AUTOSAR XML (schema 4-2-2)
package /STELLANTIS/EPT/ASWCs
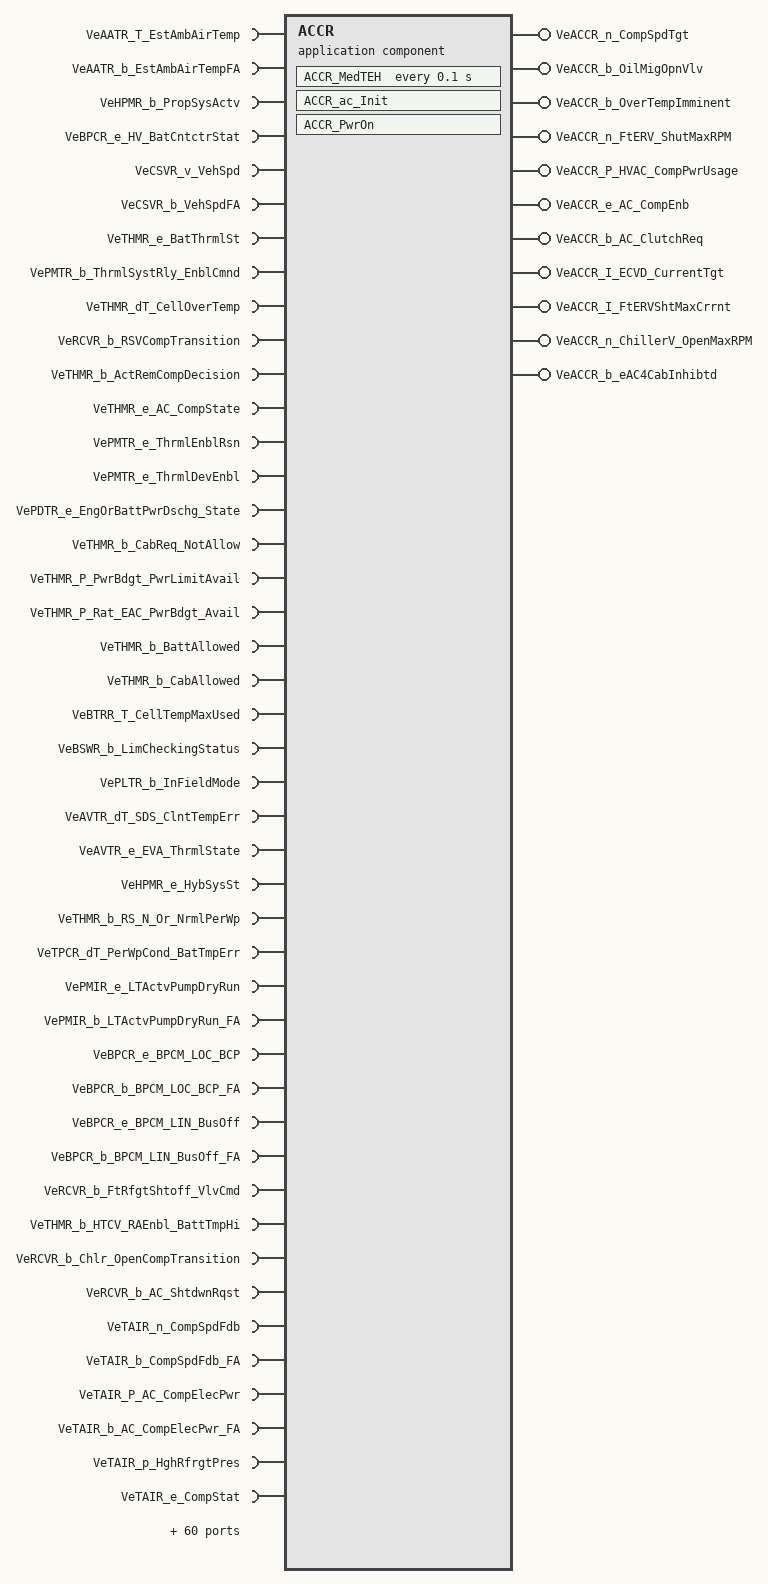
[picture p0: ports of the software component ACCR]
  application sw component type ACCR
    104 x require port:
      VeAATR_T_EstAmbAirTemp: variation-point={short-label=vpVeAATR_T_EstAmbAirTemp, sw-syscond=1}, nonqueued-receiver-com-spec{data-element=Value, init-value=0}, required-interface=VeAATR_T_EstAmbAirTemp
      VeAATR_b_EstAmbAirTempFA: variation-point={short-label=vpVeAATR_b_EstAmbAirTempFA, sw-syscond=1}, nonqueued-receiver-com-spec{data-element=Value, init-value=0}, required-interface=VeAATR_b_EstAmbAirTempFA
      VeHPMR_b_PropSysActv: variation-point={short-label=vpVeHPMR_b_PropSysActv, sw-syscond=1}, nonqueued-receiver-com-spec{data-element=Value, init-value=0}, required-interface=VeHPMR_b_PropSysActv
      VeBPCR_e_HV_BatCntctrStat: variation-point={short-label=vpVeBPCR_e_HV_BatCntctrStat, sw-syscond=1}, nonqueued-receiver-com-spec{data-element=Value, init-value=CeHVTR_e_Open}, required-interface=VeBPCR_e_HV_BatCntctrStat
      VeCSVR_v_VehSpd: variation-point={short-label=vpVeCSVR_v_VehSpd, sw-syscond=1}, nonqueued-receiver-com-spec{data-element=Value, init-value=0}, required-interface=VeCSVR_v_VehSpd
      VeCSVR_b_VehSpdFA: variation-point={short-label=vpVeCSVR_b_VehSpdFA, sw-syscond=1}, nonqueued-receiver-com-spec{data-element=Value, init-value=0}, required-interface=VeCSVR_b_VehSpdFA
      VeTHMR_e_BatThrmlSt: variation-point={short-label=vpVeTHMR_e_BatThrmlSt, sw-syscond=1}, nonqueued-receiver-com-spec{data-element=Value, init-value=CeTHMR_e_NoConditioning}, required-interface=VeTHMR_e_BatThrmlSt
      VePMTR_b_ThrmlSystRly_EnblCmnd: variation-point={short-label=vpVePMTR_b_ThrmlSystRly_EnblCmnd, sw-syscond=1}, nonqueued-receiver-com-spec{data-element=Value, init-value=0}, required-interface=VePMTR_b_ThrmlSystRly_EnblCmnd
      VeTHMR_dT_CellOverTemp: variation-point={short-label=vpVeTHMR_dT_CellOverTemp, sw-syscond=1}, nonqueued-receiver-com-spec{data-element=Value, init-value=0}, required-interface=VeTHMR_dT_CellOverTemp
      VeRCVR_b_RSVCompTransition: variation-point={short-label=vpVeRCVR_b_RSVCompTransition, sw-syscond=1}, nonqueued-receiver-com-spec{data-element=Value, init-value=0}, required-interface=VeRCVR_b_RSVCompTransition
      VeTHMR_b_ActRemCompDecision: variation-point={short-label=vpVeTHMR_b_ActRemCompDecision, sw-syscond=1}, nonqueued-receiver-com-spec{data-element=Value, init-value=0}, required-interface=VeTHMR_b_ActRemCompDecision
      VeTHMR_e_AC_CompState: variation-point={short-label=vpVeTHMR_e_AC_CompState, sw-syscond=1}, nonqueued-receiver-com-spec{data-element=Value, init-value=CeTHMR_e_ACOff}, required-interface=VeTHMR_e_AC_CompState
      VePMTR_e_ThrmlEnblRsn: variation-point={short-label=vpVePMTR_e_ThrmlEnblRsn, sw-syscond=1}, nonqueued-receiver-com-spec{data-element=Value, init-value=CePMTR_e_EnblKey_Acc_or_DrvDoorAjr}, required-interface=VePMTR_e_ThrmlEnblRsn
      VePMTR_e_ThrmlDevEnbl: variation-point={short-label=vpVePMTR_e_ThrmlDevEnbl, sw-syscond=1}, nonqueued-receiver-com-spec{data-element=Value, init-value=CePMTR_e_DISBL_All_Thrml}, required-interface=VePMTR_e_ThrmlDevEnbl
      VePDTR_e_EngOrBattPwrDschg_State: variation-point={short-label=vpVePDTR_e_EngOrBattPwrDschg_State, sw-syscond=1}, nonqueued-receiver-com-spec{data-element=Value, init-value=CePDTR_e_No_Dischrg}, required-interface=VePDTR_e_EngOrBattPwrDschg_State
      VeTHMR_b_CabReq_NotAllow: variation-point={short-label=vpVeTHMR_b_CabReq_NotAllow, sw-syscond=1}, nonqueued-receiver-com-spec{data-element=Value, init-value=0}, required-interface=VeTHMR_b_CabReq_NotAllow
      VeTHMR_P_PwrBdgt_PwrLimitAvail: variation-point={short-label=vpVeTHMR_P_PwrBdgt_PwrLimitAvail, sw-syscond=1}, nonqueued-receiver-com-spec{data-element=Value, init-value=0}, required-interface=VeTHMR_P_PwrBdgt_PwrLimitAvail
      VeTHMR_P_Rat_EAC_PwrBdgt_Avail: variation-point={short-label=vpVeTHMR_P_Rat_EAC_PwrBdgt_Avail, sw-syscond=1}, nonqueued-receiver-com-spec{data-element=Value, init-value=0}, required-interface=VeTHMR_P_Rat_EAC_PwrBdgt_Avail
      VeTHMR_b_BattAllowed: variation-point={short-label=vpVeTHMR_b_BattAllowed, sw-syscond=1}, nonqueued-receiver-com-spec{data-element=Value, init-value=0}, required-interface=VeTHMR_b_BattAllowed
      VeTHMR_b_CabAllowed: variation-point={short-label=vpVeTHMR_b_CabAllowed, sw-syscond=1}, nonqueued-receiver-com-spec{data-element=Value, init-value=0}, required-interface=VeTHMR_b_CabAllowed
      VeBTRR_T_CellTempMaxUsed: variation-point={short-label=vpVeBTRR_T_CellTempMaxUsed, sw-syscond=1}, nonqueued-receiver-com-spec{data-element=Value, init-value=0}, required-interface=VeBTRR_T_CellTempMaxUsed
      VeBSWR_b_LimCheckingStatus: variation-point={short-label=vpVeBSWR_b_LimCheckingStatus, sw-syscond=1}, nonqueued-receiver-com-spec{data-element=Value, init-value=0}, required-interface=VeBSWR_b_LimCheckingStatus
      VePLTR_b_InFieldMode: variation-point={short-label=vpVePLTR_b_InFieldMode, sw-syscond=1}, nonqueued-receiver-com-spec{data-element=Value, init-value=0}, required-interface=VePLTR_b_InFieldMode
      VeAVTR_dT_SDS_ClntTempErr: variation-point={short-label=vpVeAVTR_dT_SDS_ClntTempErr, sw-syscond=1}, nonqueued-receiver-com-spec{data-element=Value, init-value=0}, required-interface=VeAVTR_dT_SDS_ClntTempErr
      VeAVTR_e_EVA_ThrmlState: variation-point={short-label=vpVeAVTR_e_EVA_ThrmlState, sw-syscond=1}, nonqueued-receiver-com-spec{data-element=Value, init-value=CeAVTR_e_NoEVACond}, required-interface=VeAVTR_e_EVA_ThrmlState
      VeHPMR_e_HybSysSt: variation-point={short-label=vpVeHPMR_e_HybSysSt, sw-syscond=1}, nonqueued-receiver-com-spec{data-element=Value, init-value=CeHPMR_e_POWERUP}, required-interface=VeHPMR_e_HybSysSt
      VeTHMR_b_RS_N_Or_NrmlPerWp: variation-point={short-label=vpVeTHMR_b_RS_N_Or_NrmlPerWp, sw-syscond=1}, nonqueued-receiver-com-spec{data-element=Value, init-value=0}, required-interface=VeTHMR_b_RS_N_Or_NrmlPerWp
      VeTPCR_dT_PerWpCond_BatTmpErr: variation-point={short-label=vpVeTPCR_dT_PerWpCond_BatTmpErr, sw-syscond=1}, nonqueued-receiver-com-spec{data-element=Value, init-value=0}, required-interface=VeTPCR_dT_PerWpCond_BatTmpErr
      VePMIR_e_LTActvPumpDryRun: variation-point={short-label=vpVePMIR_e_LTActvPumpDryRun, sw-syscond=1}, nonqueued-receiver-com-spec{data-element=Value, init-value=CePMPR_e_FTSNA_False}, required-interface=VePMIR_e_LTActvPumpDryRun
      VePMIR_b_LTActvPumpDryRun_FA: variation-point={short-label=vpVePMIR_b_LTActvPumpDryRun_FA, sw-syscond=1}, nonqueued-receiver-com-spec{data-element=Value, init-value=0}, required-interface=VePMIR_b_LTActvPumpDryRun_FA
      VeBPCR_e_BPCM_LOC_BCP: variation-point={short-label=vpVeBPCR_e_BPCM_LOC_BCP, sw-syscond=1}, nonqueued-receiver-com-spec{data-element=Value, init-value=CeBPCR_e_LOC_BCP_False}, required-interface=VeBPCR_e_BPCM_LOC_BCP
      VeBPCR_b_BPCM_LOC_BCP_FA: variation-point={short-label=vpVeBPCR_b_BPCM_LOC_BCP_FA, sw-syscond=1}, nonqueued-receiver-com-spec{data-element=Value, init-value=0}, required-interface=VeBPCR_b_BPCM_LOC_BCP_FA
      VeBPCR_e_BPCM_LIN_BusOff: variation-point={short-label=vpVeBPCR_e_BPCM_LIN_BusOff, sw-syscond=1}, nonqueued-receiver-com-spec{data-element=Value, init-value=CeBPCR_e_LIN_BusOff_Disabled}, required-interface=VeBPCR_e_BPCM_LIN_BusOff
      VeBPCR_b_BPCM_LIN_BusOff_FA: variation-point={short-label=vpVeBPCR_b_BPCM_LIN_BusOff_FA, sw-syscond=1}, nonqueued-receiver-com-spec{data-element=Value, init-value=0}, required-interface=VeBPCR_b_BPCM_LIN_BusOff_FA
      VeRCVR_b_FtRfgtShtoff_VlvCmd: variation-point={short-label=vpVeRCVR_b_FtRfgtShtoff_VlvCmd, sw-syscond=1}, nonqueued-receiver-com-spec{data-element=Value, init-value=0}, required-interface=VeRCVR_b_FtRfgtShtoff_VlvCmd
      VeTHMR_b_HTCV_RAEnbl_BattTmpHi: variation-point={short-label=vpVeTHMR_b_HTCV_RAEnbl_BattTmpHi, sw-syscond=1}, nonqueued-receiver-com-spec{data-element=Value, init-value=0}, required-interface=VeTHMR_b_HTCV_RAEnbl_BattTmpHi
      VeRCVR_b_Chlr_OpenCompTransition: variation-point={short-label=vpVeRCVR_b_Chlr_OpenCompTransition, sw-syscond=1}, nonqueued-receiver-com-spec{data-element=Value, init-value=0}, required-interface=VeRCVR_b_Chlr_OpenCompTransition
      VeRCVR_b_AC_ShtdwnRqst: variation-point={short-label=vpVeRCVR_b_AC_ShtdwnRqst, sw-syscond=1}, nonqueued-receiver-com-spec{data-element=Value, init-value=0}, required-interface=VeRCVR_b_AC_ShtdwnRqst
      VeTAIR_n_CompSpdFdb: variation-point={short-label=vpVeTAIR_n_CompSpdFdb, sw-syscond=1}, nonqueued-receiver-com-spec{data-element=Value, init-value=0}, required-interface=VeTAIR_n_CompSpdFdb
      VeTAIR_b_CompSpdFdb_FA: variation-point={short-label=vpVeTAIR_b_CompSpdFdb_FA, sw-syscond=1}, nonqueued-receiver-com-spec{data-element=Value, init-value=0}, required-interface=VeTAIR_b_CompSpdFdb_FA
      VeTAIR_P_AC_CompElecPwr: variation-point={short-label=vpVeTAIR_P_AC_CompElecPwr, sw-syscond=1}, nonqueued-receiver-com-spec{data-element=Value, init-value=0}, required-interface=VeTAIR_P_AC_CompElecPwr
      VeTAIR_b_AC_CompElecPwr_FA: variation-point={short-label=vpVeTAIR_b_AC_CompElecPwr_FA, sw-syscond=1}, nonqueued-receiver-com-spec{data-element=Value, init-value=0}, required-interface=VeTAIR_b_AC_CompElecPwr_FA
      VeTAIR_p_HghRfrgtPres: variation-point={short-label=vpVeTAIR_p_HghRfrgtPres, sw-syscond=1}, nonqueued-receiver-com-spec{data-element=Value, init-value=0}, required-interface=VeTAIR_p_HghRfrgtPres
      VeTAIR_e_CompStat: variation-point={short-label=vpVeTAIR_e_CompStat, sw-syscond=1}, nonqueued-receiver-com-spec{data-element=Value, init-value=CeTAIR_e_NormalOp}, required-interface=VeTAIR_e_CompStat
      VeTAIR_b_CompSpdIncrReq: variation-point={short-label=vpVeTAIR_b_CompSpdIncrReq, sw-syscond=1}, nonqueued-receiver-com-spec{data-element=Value, init-value=0}, required-interface=VeTAIR_b_CompSpdIncrReq
      VeTAIR_b_ACCompReq: variation-point={short-label=vpVeTAIR_b_ACCompReq, sw-syscond=1}, nonqueued-receiver-com-spec{data-element=Value, init-value=0}, required-interface=VeTAIR_b_ACCompReq
      VeTAIR_T_CompBoardTemp: variation-point={short-label=vpVeTAIR_T_CompBoardTemp, sw-syscond=1}, nonqueued-receiver-com-spec{data-element=Value, init-value=0}, required-interface=VeTAIR_T_CompBoardTemp
      VeTAIR_b_CompBoardTemp_FA: variation-point={short-label=vpVeTAIR_b_CompBoardTemp_FA, sw-syscond=1}, nonqueued-receiver-com-spec{data-element=Value, init-value=0}, required-interface=VeTAIR_b_CompBoardTemp_FA
      VeTAIR_T_FtEvapTmp: variation-point={short-label=vpVeTAIR_T_FtEvapTmp, sw-syscond=1}, nonqueued-receiver-com-spec{data-element=Value, init-value=0}, required-interface=VeTAIR_T_FtEvapTmp
      VeTAIR_b_FtEvapTmp_FA: variation-point={short-label=vpVeTAIR_b_FtEvapTmp_FA, sw-syscond=1}, nonqueued-receiver-com-spec{data-element=Value, init-value=0}, required-interface=VeTAIR_b_FtEvapTmp_FA
      VeTAIR_T_FtEvapTmp_Tgt: variation-point={short-label=vpVeTAIR_T_FtEvapTmp_Tgt, sw-syscond=1}, nonqueued-receiver-com-spec{data-element=Value, init-value=0}, required-interface=VeTAIR_T_FtEvapTmp_Tgt
      VeTAIR_b_FtEvapTmp_TgtFA: variation-point={short-label=vpVeTAIR_b_FtEvapTmp_TgtFA, sw-syscond=1}, nonqueued-receiver-com-spec{data-element=Value, init-value=0}, required-interface=VeTAIR_b_FtEvapTmp_TgtFA
      VeTAIR_e_CompSpdTgt_IO_CntrlSt: variation-point={short-label=vpVeTAIR_e_CompSpdTgt_IO_CntrlSt, sw-syscond=1}, nonqueued-receiver-com-spec{data-element=Value, init-value=CeTAIR_e_Return_Control_to_ECU}, required-interface=VeTAIR_e_CompSpdTgt_IO_CntrlSt
      VeTAIR_n_DVC_CompSpdTgt: variation-point={short-label=vpVeTAIR_n_DVC_CompSpdTgt, sw-syscond=1}, nonqueued-receiver-com-spec{data-element=Value, init-value=0}, required-interface=VeTAIR_n_DVC_CompSpdTgt
      VeTAIR_b_HVAC_ECVD_CurrentActFA: variation-point={short-label=vpVeTAIR_b_HVAC_ECVD_CurrentActFA, sw-syscond=1}, nonqueued-receiver-com-spec{data-element=Value, init-value=0}, required-interface=VeTAIR_b_HVAC_ECVD_CurrentActFA
      VeHCDR_e_BatteryThermalFault: variation-point={short-label=vpVeHCDR_e_BatteryThermalFault, sw-syscond=1}, nonqueued-receiver-com-spec{data-element=Value, init-value=CeHCDR_e_BattThermalNoFault}, required-interface=VeHCDR_e_BatteryThermalFault
      VeHCDR_b_AC_Comp_Fault: variation-point={short-label=vpVeHCDR_b_AC_Comp_Fault, sw-syscond=1}, nonqueued-receiver-com-spec{data-element=Value, init-value=0}, required-interface=VeHCDR_b_AC_Comp_Fault
      VeTAIR_Pct_FrtBlwrCmd: variation-point={short-label=vpVeTAIR_Pct_FrtBlwrCmd, sw-syscond=1}, nonqueued-receiver-com-spec{data-element=Value, init-value=0}, required-interface=VeTAIR_Pct_FrtBlwrCmd
      VeTAIR_b_FrtBlwrCmd_FA: variation-point={short-label=vpVeTAIR_b_FrtBlwrCmd_FA, sw-syscond=1}, nonqueued-receiver-com-spec{data-element=Value, init-value=0}, required-interface=VeTAIR_b_FrtBlwrCmd_FA
      VeVLDR_b_EXV_PressElctrFlt_FltDtct: variation-point={short-label=vpVeVLDR_b_EXV_PressElctrFlt_FltDtct, sw-syscond=1}, nonqueued-receiver-com-spec{data-element=Value, init-value=0}, required-interface=VeVLDR_b_EXV_PressElctrFlt_FltDtct
      VeVLDR_b_EXV_TempElctrFlt_FltDtct: variation-point={short-label=vpVeVLDR_b_EXV_TempElctrFlt_FltDtct, sw-syscond=1}, nonqueued-receiver-com-spec{data-element=Value, init-value=0}, required-interface=VeVLDR_b_EXV_TempElctrFlt_FltDtct
      VeTAIR_T_CompIGBTTemp: variation-point={short-label=vpVeTAIR_T_CompIGBTTemp, sw-syscond=1}, nonqueued-receiver-com-spec{data-element=Value, init-value=0}, required-interface=VeTAIR_T_CompIGBTTemp
      VeTAIR_b_CompIGBTTemp_FA: variation-point={short-label=vpVeTAIR_b_CompIGBTTemp_FA, sw-syscond=1}, nonqueued-receiver-com-spec{data-element=Value, init-value=0}, required-interface=VeTAIR_b_CompIGBTTemp_FA
      VeVLDR_b_EXV_PressSens_FltDtct: variation-point={short-label=vpVeVLDR_b_EXV_PressSens_FltDtct, sw-syscond=1}, nonqueued-receiver-com-spec{data-element=Value, init-value=0}, required-interface=VeVLDR_b_EXV_PressSens_FltDtct
      VeVLDR_b_EXV_TempSens_FltDtct: variation-point={short-label=vpVeVLDR_b_EXV_TempSens_FltDtct, sw-syscond=1}, nonqueued-receiver-com-spec{data-element=Value, init-value=0}, required-interface=VeVLDR_b_EXV_TempSens_FltDtct
      VeTHMR_e_CabCoolThermalState: variation-point={short-label=vpVeTHMR_e_CabCoolThermalState, sw-syscond=1}, nonqueued-receiver-com-spec{data-element=Value, init-value=CeTHMR_e_NoCabinCooling}, required-interface=VeTHMR_e_CabCoolThermalState
      VeBTRR_b_BattCoolReq_CPV_RA: variation-point={short-label=vpVeBTRR_b_BattCoolReq_CPV_RA, sw-syscond=1}, nonqueued-receiver-com-spec{data-element=Value, init-value=0}, required-interface=VeBTRR_b_BattCoolReq_CPV_RA
      VeRCVR_b_EXV_PresSensrRA: variation-point={short-label=vpVeRCVR_b_EXV_PresSensrRA, sw-syscond=1}, nonqueued-receiver-com-spec{data-element=Value, init-value=0}, required-interface=VeRCVR_b_EXV_PresSensrRA
      VeTRIR_e_HVACECOModeSts: variation-point={short-label=vpVeTRIR_e_HVACECOModeSts, sw-syscond=1}, nonqueued-receiver-com-spec{data-element=Value, init-value=CeTRIR_e_HVAC_ECO_OFF}, required-interface=VeTRIR_e_HVACECOModeSts
      VeTHMR_b_DeiceActv: variation-point={short-label=vpVeTHMR_b_DeiceActv, sw-syscond=1}, nonqueued-receiver-com-spec{data-element=Value, init-value=0}, required-interface=VeTHMR_b_DeiceActv
      VeTHMR_e_CabHeatThermalMode: variation-point={short-label=vpVeTHMR_e_CabHeatThermalMode, sw-syscond=1}, nonqueued-receiver-com-spec{data-element=Value, init-value=CeTHMR_e_NoActvHeat}, required-interface=VeTHMR_e_CabHeatThermalMode
      VeCTRR_dT_HeatPumpErr: variation-point={short-label=vpVeCTRR_dT_HeatPumpErr, sw-syscond=1}, nonqueued-receiver-com-spec{data-element=Value, init-value=0}, required-interface=VeCTRR_dT_HeatPumpErr
      VeRCVR_p_eACSuctionPressure: variation-point={short-label=vpVeRCVR_p_eACSuctionPressure, sw-syscond=1}, nonqueued-receiver-com-spec{data-element=Value, init-value=0}, required-interface=VeRCVR_p_eACSuctionPressure
      VeDMAB_y_StatusByte_EvapRefrishutoffCtrlShrtGndFlt: variation-point={short-label=vpVeDMAB_y_StatusByte_EvapRefrishutoffCtrlShrtGndFlt, sw-syscond=1}, nonqueued-receiver-com-spec{data-element=Value, init-value=0}, required-interface=VeDMAB_y_StatusByte_EvapRefrishutoffCtrlShrtGndFlt
      VeDMAB_y_StatusByte_CommBusOff: variation-point={short-label=vpVeDMAB_y_StatusByte_CommBusOff, sw-syscond=1}, nonqueued-receiver-com-spec{data-element=Value, init-value=0}, required-interface=VeDMAB_y_StatusByte_CommBusOff
      VeDMAB_y_StatusByte_LosCommBECM_A: variation-point={short-label=vpVeDMAB_y_StatusByte_LosCommBECM_A, sw-syscond=1}, nonqueued-receiver-com-spec{data-element=Value, init-value=0}, required-interface=VeDMAB_y_StatusByte_LosCommBECM_A
      VeDMAB_y_StatusByte_EvapRefriShutoffCtrlshrtBattFlt: variation-point={short-label=vpVeDMAB_y_StatusByte_EvapRefriShutoffCtrlshrtBattFlt, sw-syscond=1}, nonqueued-receiver-com-spec{data-element=Value, init-value=0}, required-interface=VeDMAB_y_StatusByte_EvapRefriShutoffCtrlshrtBattFlt
      VeDMAB_y_StatusByte_CommBus_B_Off: variation-point={short-label=vpVeDMAB_y_StatusByte_CommBus_B_Off, sw-syscond=1}, nonqueued-receiver-com-spec{data-element=Value, init-value=0}, required-interface=VeDMAB_y_StatusByte_CommBus_B_Off
      VeDMAB_y_StatusByte_LIN2_BusOff: variation-point={short-label=vpVeDMAB_y_StatusByte_LIN2_BusOff, sw-syscond=1}, nonqueued-receiver-com-spec{data-element=Value, init-value=0}, required-interface=VeDMAB_y_StatusByte_LIN2_BusOff
      VeDMAB_y_StatusByte_LostCommEAC: variation-point={short-label=vpVeDMAB_y_StatusByte_LostCommEAC, sw-syscond=1}, nonqueued-receiver-com-spec{data-element=Value, init-value=0}, required-interface=VeDMAB_y_StatusByte_LostCommEAC
      VeTHMR_T_PPCTIS_Arb: variation-point={short-label=vpVeTHMR_T_PPCTIS_Arb, sw-syscond=1}, nonqueued-receiver-com-spec{data-element=Value, init-value=0}, required-interface=VeTHMR_T_PPCTIS_Arb
      VeDMAB_y_StatusByte_CoolCtrlVlv1CktHi: variation-point={short-label=vpVeDMAB_y_StatusByte_CoolCtrlVlv1CktHi, sw-syscond=1}, nonqueued-receiver-com-spec{data-element=Value, init-value=0}, required-interface=VeDMAB_y_StatusByte_CoolCtrlVlv1CktHi
      VeDMAB_y_StatusByte_CoolCtrlVlv1CktLo: variation-point={short-label=vpVeDMAB_y_StatusByte_CoolCtrlVlv1CktLo, sw-syscond=1}, nonqueued-receiver-com-spec{data-element=Value, init-value=0}, required-interface=VeDMAB_y_StatusByte_CoolCtrlVlv1CktLo
      VeDMAB_y_StatusByte_LostCommACRefrigExpVlvActA: variation-point={short-label=vpVeDMAB_y_StatusByte_LostCommACRefrigExpVlvActA, sw-syscond=1}, nonqueued-receiver-com-spec{data-element=Value, init-value=0}, required-interface=VeDMAB_y_StatusByte_LostCommACRefrigExpVlvActA
      VeDMAB_y_StatusByte_LosCommBECM_A_CANC11: variation-point={short-label=vpVeDMAB_y_StatusByte_LosCommBECM_A_CANC11, sw-syscond=1}, nonqueued-receiver-com-spec{data-element=Value, init-value=0}, required-interface=VeDMAB_y_StatusByte_LosCommBECM_A_CANC11
      VeDMAB_y_StatusByte_BattCoolPmpPerf: variation-point={short-label=vpVeDMAB_y_StatusByte_BattCoolPmpPerf, sw-syscond=1}, nonqueued-receiver-com-spec{data-element=Value, init-value=0}, required-interface=VeDMAB_y_StatusByte_BattCoolPmpPerf
      VeOBCR_e_ChargingLevel: variation-point={short-label=vpVeOBCR_e_ChargingLevel, sw-syscond=1}, nonqueued-receiver-com-spec{data-element=Value, init-value=CeOBCR_e_ChargingLvlDefault}, required-interface=VeOBCR_e_ChargingLevel
      VeDMAB_y_StatusByte_EACPerf: variation-point={short-label=vpVeDMAB_y_StatusByte_EACPerf, sw-syscond=1}, nonqueued-receiver-com-spec{data-element=Value, init-value=0}, required-interface=VeDMAB_y_StatusByte_EACPerf
      VeDMAB_y_StatusByte_AC_RefrigPresSnsrALo: variation-point={short-label=vpVeDMAB_y_StatusByte_AC_RefrigPresSnsrALo, sw-syscond=1}, nonqueued-receiver-com-spec{data-element=Value, init-value=0}, required-interface=VeDMAB_y_StatusByte_AC_RefrigPresSnsrALo
      VeDMAB_y_StatusByte_AC_RefrigPresSnsrAHi: variation-point={short-label=vpVeDMAB_y_StatusByte_AC_RefrigPresSnsrAHi, sw-syscond=1}, nonqueued-receiver-com-spec{data-element=Value, init-value=0}, required-interface=VeDMAB_y_StatusByte_AC_RefrigPresSnsrAHi
      VeDMAB_y_StatusByte_AC_RefrigPresSnsrAPerf: variation-point={short-label=vpVeDMAB_y_StatusByte_AC_RefrigPresSnsrAPerf, sw-syscond=1}, nonqueued-receiver-com-spec{data-element=Value, init-value=0}, required-interface=VeDMAB_y_StatusByte_AC_RefrigPresSnsrAPerf
      VeDMAB_y_StatusByte_AC_RefrigTempSnsrCPerf: variation-point={short-label=vpVeDMAB_y_StatusByte_AC_RefrigTempSnsrCPerf, sw-syscond=1}, nonqueued-receiver-com-spec{data-element=Value, init-value=0}, required-interface=VeDMAB_y_StatusByte_AC_RefrigTempSnsrCPerf
      VeDMAB_y_StatusByte_AC_RefrigPresSnsrCCktPerf: variation-point={short-label=vpVeDMAB_y_StatusByte_AC_RefrigPresSnsrCCktPerf, sw-syscond=1}, nonqueued-receiver-com-spec{data-element=Value, init-value=0}, required-interface=VeDMAB_y_StatusByte_AC_RefrigPresSnsrCCktPerf
      VeDMAB_y_StatusByte_AC_RefrigExpVlvAct_C_CntrlCktPerf: variation-point={short-label=vpVeDMAB_y_StatusByte_AC_RefrigExpVlvAct_C_CntrlCktPerf, sw-syscond=1}, nonqueued-receiver-com-spec{data-element=Value, init-value=0}, required-interface=VeDMAB_y_StatusByte_AC_RefrigExpVlvAct_C_CntrlCktPerf
      VeDMAB_y_StatusByte_AC_RefrigPresSnsrCCkt: variation-point={short-label=vpVeDMAB_y_StatusByte_AC_RefrigPresSnsrCCkt, sw-syscond=1}, nonqueued-receiver-com-spec{data-element=Value, init-value=0}, required-interface=VeDMAB_y_StatusByte_AC_RefrigPresSnsrCCkt
      VeDMAB_y_StatusByte_AC_RefrigTempSnsrCCkt: variation-point={short-label=vpVeDMAB_y_StatusByte_AC_RefrigTempSnsrCCkt, sw-syscond=1}, nonqueued-receiver-com-spec{data-element=Value, init-value=0}, required-interface=VeDMAB_y_StatusByte_AC_RefrigTempSnsrCCkt
      VeDMAB_y_StatusByte_LostCommACRefrigExpVlvActC: variation-point={short-label=vpVeDMAB_y_StatusByte_LostCommACRefrigExpVlvActC, sw-syscond=1}, nonqueued-receiver-com-spec{data-element=Value, init-value=0}, required-interface=VeDMAB_y_StatusByte_LostCommACRefrigExpVlvActC
      VeDMAB_y_StatusByte_LIN1_BusOff: variation-point={short-label=vpVeDMAB_y_StatusByte_LIN1_BusOff, sw-syscond=1}, nonqueued-receiver-com-spec{data-element=Value, init-value=0}, required-interface=VeDMAB_y_StatusByte_LIN1_BusOff
      VeDMAB_y_StatusByte_AC_RefrigTempSnsrAPerf: variation-point={short-label=vpVeDMAB_y_StatusByte_AC_RefrigTempSnsrAPerf, sw-syscond=1}, nonqueued-receiver-com-spec{data-element=Value, init-value=0}, required-interface=VeDMAB_y_StatusByte_AC_RefrigTempSnsrAPerf
      VeDMAB_y_StatusByte_AC_RefrigExpVlvActCtrCktPerf: variation-point={short-label=vpVeDMAB_y_StatusByte_AC_RefrigExpVlvActCtrCktPerf, sw-syscond=1}, nonqueued-receiver-com-spec{data-element=Value, init-value=0}, required-interface=VeDMAB_y_StatusByte_AC_RefrigExpVlvActCtrCktPerf
      VeDMAB_y_StatusByte_AC_RefrigTempSnsrBCkt: variation-point={short-label=vpVeDMAB_y_StatusByte_AC_RefrigTempSnsrBCkt, sw-syscond=1}, nonqueued-receiver-com-spec{data-element=Value, init-value=0}, required-interface=VeDMAB_y_StatusByte_AC_RefrigTempSnsrBCkt
      VeDMAB_y_StatusByte_AC_RefrigTempSnsrACkt: variation-point={short-label=vpVeDMAB_y_StatusByte_AC_RefrigTempSnsrACkt, sw-syscond=1}, nonqueued-receiver-com-spec{data-element=Value, init-value=0}, required-interface=VeDMAB_y_StatusByte_AC_RefrigTempSnsrACkt
      VeDMAB_y_StatusByte_LIN3_BusOff: variation-point={short-label=vpVeDMAB_y_StatusByte_LIN3_BusOff, sw-syscond=1}, nonqueued-receiver-com-spec{data-element=Value, init-value=0}, required-interface=VeDMAB_y_StatusByte_LIN3_BusOff
      VeDMAB_y_StatusByte_AC_RefrigExpVlvActD_CntrlCktPerf: variation-point={short-label=vpVeDMAB_y_StatusByte_AC_RefrigExpVlvActD_CntrlCktPerf, sw-syscond=1}, nonqueued-receiver-com-spec{data-element=Value, init-value=0}, required-interface=VeDMAB_y_StatusByte_AC_RefrigExpVlvActD_CntrlCktPerf
    11 x provide port:
      VeACCR_n_CompSpdTgt: variation-point={short-label=vpVeACCR_n_CompSpdTgt, sw-syscond=1}, nonqueued-sender-com-spec{data-element=Value, init-value=0}, provided-interface=VeACCR_n_CompSpdTgt
      VeACCR_b_OilMigOpnVlv: variation-point={short-label=vpVeACCR_b_OilMigOpnVlv, sw-syscond=1}, nonqueued-sender-com-spec{data-element=Value, init-value=0}, provided-interface=VeACCR_b_OilMigOpnVlv
      VeACCR_b_OverTempImminent: variation-point={short-label=vpVeACCR_b_OverTempImminent, sw-syscond=1}, nonqueued-sender-com-spec{data-element=Value, init-value=0}, provided-interface=VeACCR_b_OverTempImminent
      VeACCR_n_FtERV_ShutMaxRPM: variation-point={short-label=vpVeACCR_n_FtERV_ShutMaxRPM, sw-syscond=1}, nonqueued-sender-com-spec{data-element=Value, init-value=0}, provided-interface=VeACCR_n_FtERV_ShutMaxRPM
      VeACCR_P_HVAC_CompPwrUsage: variation-point={short-label=vpVeACCR_P_HVAC_CompPwrUsage, sw-syscond=1}, nonqueued-sender-com-spec{data-element=Value, init-value=0}, provided-interface=VeACCR_P_HVAC_CompPwrUsage
      VeACCR_e_AC_CompEnb: variation-point={short-label=vpVeACCR_e_AC_CompEnb, sw-syscond=1}, nonqueued-sender-com-spec{data-element=Value, init-value=CeACCR_e_ACComp_Enable}, provided-interface=VeACCR_e_AC_CompEnb
      VeACCR_b_AC_ClutchReq: variation-point={short-label=vpVeACCR_b_AC_ClutchReq, sw-syscond=1}, nonqueued-sender-com-spec{data-element=Value, init-value=0}, provided-interface=VeACCR_b_AC_ClutchReq
      VeACCR_I_ECVD_CurrentTgt: variation-point={short-label=vpVeACCR_I_ECVD_CurrentTgt, sw-syscond=1}, nonqueued-sender-com-spec{data-element=Value, init-value=0}, provided-interface=VeACCR_I_ECVD_CurrentTgt
      VeACCR_I_FtERVShtMaxCrrnt: variation-point={short-label=vpVeACCR_I_FtERVShtMaxCrrnt, sw-syscond=1}, nonqueued-sender-com-spec{data-element=Value, init-value=0}, provided-interface=VeACCR_I_FtERVShtMaxCrrnt
      VeACCR_n_ChillerV_OpenMaxRPM: variation-point={short-label=vpVeACCR_n_ChillerV_OpenMaxRPM, sw-syscond=1}, nonqueued-sender-com-spec{data-element=Value, init-value=0}, provided-interface=VeACCR_n_ChillerV_OpenMaxRPM
      VeACCR_b_eAC4CabInhibtd: variation-point={short-label=vpVeACCR_b_eAC4CabInhibtd, sw-syscond=1}, nonqueued-sender-com-spec{data-element=Value, init-value=0}, provided-interface=VeACCR_b_eAC4CabInhibtd
    behavior IB_ACCR: data-type-mapping=msADTtoIDTMapping, handle-termination-and-restart=NO-SUPPORT
      timing event Event_MedTEH: start-on-event=ACCR_MedTEH, period=0.1
      init event Event_ACCR_ac_Init: start-on-event=ACCR_ac_Init
      init event Event_PwrOn: start-on-event=ACCR_PwrOn
      explicit-inter-runnable-variables:
        data OilMigOpnVlv_write_IRV: category=VALUE, sw-calibration-access=READ-ONLY, type=Boolean, init-value=0, variation-point={short-label=vpOilMigOpnVlv_write_IRV, sw-syscond=1}
        data OverTempImminent_write_IRV: category=VALUE, sw-calibration-access=READ-ONLY, type=Boolean, init-value=0, variation-point={short-label=vpOverTempImminent_write_IRV, sw-syscond=1}
      runnable ACCR_ac_Init
        data-send-points:
          access OUT_VeACCR_e_AC_CompEnb_Value: accessed-variable=VeACCR_e_AC_CompEnb.Value, variation-point={short-label=vpOUT_VeACCR_e_AC_CompEnb_Value, sw-syscond=1}
      runnable ACCR_PwrOn
        data-send-points:
          11 x access:
            OUT_VeACCR_n_CompSpdTgt_Value: accessed-variable=VeACCR_n_CompSpdTgt.Value, variation-point={short-label=vpOUT_VeACCR_n_CompSpdTgt_Value, sw-syscond=1}
            OUT_VeACCR_b_OilMigOpnVlv_Value: accessed-variable=VeACCR_b_OilMigOpnVlv.Value, variation-point={short-label=vpOUT_VeACCR_b_OilMigOpnVlv_Value, sw-syscond=1}
            OUT_VeACCR_b_eAC4CabInhibtd_Value: accessed-variable=VeACCR_b_eAC4CabInhibtd.Value, variation-point={short-label=vpOUT_VeACCR_b_eAC4CabInhibtd_Value, sw-syscond=1}
            OUT_VeACCR_b_OverTempImminent_Value: accessed-variable=VeACCR_b_OverTempImminent.Value, variation-point={short-label=vpOUT_VeACCR_b_OverTempImminent_Value, sw-syscond=1}
            OUT_VeACCR_n_FtERV_ShutMaxRPM_Value: accessed-variable=VeACCR_n_FtERV_ShutMaxRPM.Value, variation-point={short-label=vpOUT_VeACCR_n_FtERV_ShutMaxRPM_Value, sw-syscond=1}
            OUT_VeACCR_P_HVAC_CompPwrUsage_Value: accessed-variable=VeACCR_P_HVAC_CompPwrUsage.Value, variation-point={short-label=vpOUT_VeACCR_P_HVAC_CompPwrUsage_Value, sw-syscond=1}
            OUT_VeACCR_e_AC_CompEnb_Value: accessed-variable=VeACCR_e_AC_CompEnb.Value, variation-point={short-label=vpOUT_VeACCR_e_AC_CompEnb_Value, sw-syscond=1}
            OUT_VeACCR_b_AC_ClutchReq_Value: accessed-variable=VeACCR_b_AC_ClutchReq.Value, variation-point={short-label=vpOUT_VeACCR_b_AC_ClutchReq_Value, sw-syscond=1}
            OUT_VeACCR_I_ECVD_CurrentTgt_Value: accessed-variable=VeACCR_I_ECVD_CurrentTgt.Value, variation-point={short-label=vpOUT_VeACCR_I_ECVD_CurrentTgt_Value, sw-syscond=1}
            OUT_VeACCR_I_FtERVShtMaxCrrnt_Value: accessed-variable=VeACCR_I_FtERVShtMaxCrrnt.Value, variation-point={short-label=vpOUT_VeACCR_I_FtERVShtMaxCrrnt_Value, sw-syscond=1}
            OUT_VeACCR_n_ChillerV_OpenMaxRPM_Value: accessed-variable=VeACCR_n_ChillerV_OpenMaxRPM.Value, variation-point={short-label=vpOUT_VeACCR_n_ChillerV_OpenMaxRPM_Value, sw-syscond=1}
        written-local-variables:
          access WV_OilMigOpnVlv_write_IRV: accessed-variable=OilMigOpnVlv_write_IRV, variation-point={short-label=vpWV_OilMigOpnVlv_write_IRV, sw-syscond=1}
          access WV_OverTempImminent_write_IRV: accessed-variable=OverTempImminent_write_IRV, variation-point={short-label=vpWV_OverTempImminent_write_IRV, sw-syscond=1}
      runnable ACCR_MedTEH: variation-point={short-label=vpACCR_MedTEH, sw-syscond=1}
        data-receive-point-by-arguments:
          104 x access:
            IN_VeAATR_T_EstAmbAirTemp_Value: accessed-variable=VeAATR_T_EstAmbAirTemp.Value, variation-point={short-label=vpIN_VeAATR_T_EstAmbAirTemp_Value, sw-syscond=1}
            IN_VeAATR_b_EstAmbAirTempFA_Value: accessed-variable=VeAATR_b_EstAmbAirTempFA.Value, variation-point={short-label=vpIN_VeAATR_b_EstAmbAirTempFA_Value, sw-syscond=1}
            IN_VeAVTR_dT_SDS_ClntTempErr_Value: accessed-variable=VeAVTR_dT_SDS_ClntTempErr.Value, variation-point={short-label=vpIN_VeAVTR_dT_SDS_ClntTempErr_Value, sw-syscond=1}
            IN_VeAVTR_e_EVA_ThrmlState_Value: accessed-variable=VeAVTR_e_EVA_ThrmlState.Value, variation-point={short-label=vpIN_VeAVTR_e_EVA_ThrmlState_Value, sw-syscond=1}
            IN_VeBPCR_b_BPCM_LIN_BusOff_FA_Value: accessed-variable=VeBPCR_b_BPCM_LIN_BusOff_FA.Value, variation-point={short-label=vpIN_VeBPCR_b_BPCM_LIN_BusOff_FA_Value, sw-syscond=1}
            IN_VeBPCR_b_BPCM_LOC_BCP_FA_Value: accessed-variable=VeBPCR_b_BPCM_LOC_BCP_FA.Value, variation-point={short-label=vpIN_VeBPCR_b_BPCM_LOC_BCP_FA_Value, sw-syscond=1}
            IN_VeBPCR_e_BPCM_LIN_BusOff_Value: accessed-variable=VeBPCR_e_BPCM_LIN_BusOff.Value, variation-point={short-label=vpIN_VeBPCR_e_BPCM_LIN_BusOff_Value, sw-syscond=1}
            IN_VeBPCR_e_BPCM_LOC_BCP_Value: accessed-variable=VeBPCR_e_BPCM_LOC_BCP.Value, variation-point={short-label=vpIN_VeBPCR_e_BPCM_LOC_BCP_Value, sw-syscond=1}
            IN_VeBPCR_e_HV_BatCntctrStat_Value: accessed-variable=VeBPCR_e_HV_BatCntctrStat.Value, variation-point={short-label=vpIN_VeBPCR_e_HV_BatCntctrStat_Value, sw-syscond=1}
            IN_VeBSWR_b_LimCheckingStatus_Value: accessed-variable=VeBSWR_b_LimCheckingStatus.Value, variation-point={short-label=vpIN_VeBSWR_b_LimCheckingStatus_Value, sw-syscond=1}
            IN_VeBTRR_T_CellTempMaxUsed_Value: accessed-variable=VeBTRR_T_CellTempMaxUsed.Value, variation-point={short-label=vpIN_VeBTRR_T_CellTempMaxUsed_Value, sw-syscond=1}
            IN_VeBTRR_b_BattCoolReq_CPV_RA_Value: accessed-variable=VeBTRR_b_BattCoolReq_CPV_RA.Value, variation-point={short-label=vpIN_VeBTRR_b_BattCoolReq_CPV_RA_Value, sw-syscond=1}
            IN_VeCSVR_b_VehSpdFA_Value: accessed-variable=VeCSVR_b_VehSpdFA.Value, variation-point={short-label=vpIN_VeCSVR_b_VehSpdFA_Value, sw-syscond=1}
            IN_VeCSVR_v_VehSpd_Value: accessed-variable=VeCSVR_v_VehSpd.Value, variation-point={short-label=vpIN_VeCSVR_v_VehSpd_Value, sw-syscond=1}
            IN_VeCTRR_dT_HeatPumpErr_Value: accessed-variable=VeCTRR_dT_HeatPumpErr.Value, variation-point={short-label=vpIN_VeCTRR_dT_HeatPumpErr_Value, sw-syscond=1}
            IN_VeDMAB_y_StatusByte_AC_RefrigExpVlvActCtrCktPerf_Value: accessed-variable=VeDMAB_y_StatusByte_AC_RefrigExpVlvActCtrCktPerf.Value, variation-point={short-label=vpIN_VeDMAB_y_StatusByte_AC_RefrigExpVlvActCtrCktPerf_Value, sw-syscond=1}
            IN_VeDMAB_y_StatusByte_AC_RefrigExpVlvActD_CntrlCktPerf_Value: accessed-variable=VeDMAB_y_StatusByte_AC_RefrigExpVlvActD_CntrlCktPerf.Value, variation-point={short-label=vpIN_VeDMAB_y_StatusByte_AC_RefrigExpVlvActD_CntrlCktPerf_Value, sw-syscond=1}
            IN_VeDMAB_y_StatusByte_AC_RefrigExpVlvAct_C_CntrlCktPerf_Value: accessed-variable=VeDMAB_y_StatusByte_AC_RefrigExpVlvAct_C_CntrlCktPerf.Value, variation-point={short-label=vpIN_VeDMAB_y_StatusByte_AC_RefrigExpVlvAct_C_CntrlCktPerf_Value, sw-syscond=1}
            IN_VeDMAB_y_StatusByte_AC_RefrigPresSnsrAHi_Value: accessed-variable=VeDMAB_y_StatusByte_AC_RefrigPresSnsrAHi.Value, variation-point={short-label=vpIN_VeDMAB_y_StatusByte_AC_RefrigPresSnsrAHi_Value, sw-syscond=1}
            IN_VeDMAB_y_StatusByte_AC_RefrigPresSnsrALo_Value: accessed-variable=VeDMAB_y_StatusByte_AC_RefrigPresSnsrALo.Value, variation-point={short-label=vpIN_VeDMAB_y_StatusByte_AC_RefrigPresSnsrALo_Value, sw-syscond=1}
            IN_VeDMAB_y_StatusByte_AC_RefrigPresSnsrAPerf_Value: accessed-variable=VeDMAB_y_StatusByte_AC_RefrigPresSnsrAPerf.Value, variation-point={short-label=vpIN_VeDMAB_y_StatusByte_AC_RefrigPresSnsrAPerf_Value, sw-syscond=1}
            IN_VeDMAB_y_StatusByte_AC_RefrigPresSnsrCCkt_Value: accessed-variable=VeDMAB_y_StatusByte_AC_RefrigPresSnsrCCkt.Value, variation-point={short-label=vpIN_VeDMAB_y_StatusByte_AC_RefrigPresSnsrCCkt_Value, sw-syscond=1}
            IN_VeDMAB_y_StatusByte_AC_RefrigPresSnsrCCktPerf_Value: accessed-variable=VeDMAB_y_StatusByte_AC_RefrigPresSnsrCCktPerf.Value, variation-point={short-label=vpIN_VeDMAB_y_StatusByte_AC_RefrigPresSnsrCCktPerf_Value, sw-syscond=1}
            IN_VeDMAB_y_StatusByte_AC_RefrigTempSnsrACkt_Value: accessed-variable=VeDMAB_y_StatusByte_AC_RefrigTempSnsrACkt.Value, variation-point={short-label=vpIN_VeDMAB_y_StatusByte_AC_RefrigTempSnsrACkt_Value, sw-syscond=1}
            IN_VeDMAB_y_StatusByte_AC_RefrigTempSnsrAPerf_Value: accessed-variable=VeDMAB_y_StatusByte_AC_RefrigTempSnsrAPerf.Value, variation-point={short-label=vpIN_VeDMAB_y_StatusByte_AC_RefrigTempSnsrAPerf_Value, sw-syscond=1}
            IN_VeDMAB_y_StatusByte_AC_RefrigTempSnsrBCkt_Value: accessed-variable=VeDMAB_y_StatusByte_AC_RefrigTempSnsrBCkt.Value, variation-point={short-label=vpIN_VeDMAB_y_StatusByte_AC_RefrigTempSnsrBCkt_Value, sw-syscond=1}
            IN_VeDMAB_y_StatusByte_AC_RefrigTempSnsrCCkt_Value: accessed-variable=VeDMAB_y_StatusByte_AC_RefrigTempSnsrCCkt.Value, variation-point={short-label=vpIN_VeDMAB_y_StatusByte_AC_RefrigTempSnsrCCkt_Value, sw-syscond=1}
            IN_VeDMAB_y_StatusByte_AC_RefrigTempSnsrCPerf_Value: accessed-variable=VeDMAB_y_StatusByte_AC_RefrigTempSnsrCPerf.Value, variation-point={short-label=vpIN_VeDMAB_y_StatusByte_AC_RefrigTempSnsrCPerf_Value, sw-syscond=1}
            IN_VeDMAB_y_StatusByte_BattCoolPmpPerf_Value: accessed-variable=VeDMAB_y_StatusByte_BattCoolPmpPerf.Value, variation-point={short-label=vpIN_VeDMAB_y_StatusByte_BattCoolPmpPerf_Value, sw-syscond=1}
            IN_VeDMAB_y_StatusByte_CommBusOff_Value: accessed-variable=VeDMAB_y_StatusByte_CommBusOff.Value, variation-point={short-label=vpIN_VeDMAB_y_StatusByte_CommBusOff_Value, sw-syscond=1}
            IN_VeDMAB_y_StatusByte_CommBus_B_Off_Value: accessed-variable=VeDMAB_y_StatusByte_CommBus_B_Off.Value, variation-point={short-label=vpIN_VeDMAB_y_StatusByte_CommBus_B_Off_Value, sw-syscond=1}
            IN_VeDMAB_y_StatusByte_CoolCtrlVlv1CktHi_Value: accessed-variable=VeDMAB_y_StatusByte_CoolCtrlVlv1CktHi.Value, variation-point={short-label=vpIN_VeDMAB_y_StatusByte_CoolCtrlVlv1CktHi_Value, sw-syscond=1}
            IN_VeDMAB_y_StatusByte_CoolCtrlVlv1CktLo_Value: accessed-variable=VeDMAB_y_StatusByte_CoolCtrlVlv1CktLo.Value, variation-point={short-label=vpIN_VeDMAB_y_StatusByte_CoolCtrlVlv1CktLo_Value, sw-syscond=1}
            IN_VeDMAB_y_StatusByte_EACPerf_Value: accessed-variable=VeDMAB_y_StatusByte_EACPerf.Value, variation-point={short-label=vpIN_VeDMAB_y_StatusByte_EACPerf_Value, sw-syscond=1}
            IN_VeDMAB_y_StatusByte_EvapRefriShutoffCtrlshrtBattFlt_Value: accessed-variable=VeDMAB_y_StatusByte_EvapRefriShutoffCtrlshrtBattFlt.Value, variation-point={short-label=vpIN_VeDMAB_y_StatusByte_EvapRefriShutoffCtrlshrtBattFlt_Value, sw-syscond=1}
            IN_VeDMAB_y_StatusByte_EvapRefrishutoffCtrlShrtGndFlt_Value: accessed-variable=VeDMAB_y_StatusByte_EvapRefrishutoffCtrlShrtGndFlt.Value, variation-point={short-label=vpIN_VeDMAB_y_StatusByte_EvapRefrishutoffCtrlShrtGndFlt_Value, sw-syscond=1}
            IN_VeDMAB_y_StatusByte_LIN{1..3}_BusOff_Value: accessed-variable=VeDMAB_y_StatusByte_LIN{1..3}_BusOff.Value, variation-point={short-label=vpIN_VeDMAB_y_StatusByte_LIN{1..3}_BusOff_Value, sw-syscond=1}
            IN_VeDMAB_y_StatusByte_LosCommBECM_A_Value: accessed-variable=VeDMAB_y_StatusByte_LosCommBECM_A.Value, variation-point={short-label=vpIN_VeDMAB_y_StatusByte_LosCommBECM_A_Value, sw-syscond=1}
            IN_VeDMAB_y_StatusByte_LosCommBECM_A_CANC11_Value: accessed-variable=VeDMAB_y_StatusByte_LosCommBECM_A_CANC11.Value, variation-point={short-label=vpIN_VeDMAB_y_StatusByte_LosCommBECM_A_CANC11_Value, sw-syscond=1}
            IN_VeDMAB_y_StatusByte_LostCommACRefrigExpVlvActA_Value: accessed-variable=VeDMAB_y_StatusByte_LostCommACRefrigExpVlvActA.Value, variation-point={short-label=vpIN_VeDMAB_y_StatusByte_LostCommACRefrigExpVlvActA_Value, sw-syscond=1}
            IN_VeDMAB_y_StatusByte_LostCommACRefrigExpVlvActC_Value: accessed-variable=VeDMAB_y_StatusByte_LostCommACRefrigExpVlvActC.Value, variation-point={short-label=vpIN_VeDMAB_y_StatusByte_LostCommACRefrigExpVlvActC_Value, sw-syscond=1}
            IN_VeDMAB_y_StatusByte_LostCommEAC_Value: accessed-variable=VeDMAB_y_StatusByte_LostCommEAC.Value, variation-point={short-label=vpIN_VeDMAB_y_StatusByte_LostCommEAC_Value, sw-syscond=1}
            IN_VeHCDR_b_AC_Comp_Fault_Value: accessed-variable=VeHCDR_b_AC_Comp_Fault.Value, variation-point={short-label=vpIN_VeHCDR_b_AC_Comp_Fault_Value, sw-syscond=1}
            IN_VeHCDR_e_BatteryThermalFault_Value: accessed-variable=VeHCDR_e_BatteryThermalFault.Value, variation-point={short-label=vpIN_VeHCDR_e_BatteryThermalFault_Value, sw-syscond=1}
            IN_VeHPMR_b_PropSysActv_Value: accessed-variable=VeHPMR_b_PropSysActv.Value, variation-point={short-label=vpIN_VeHPMR_b_PropSysActv_Value, sw-syscond=1}
            IN_VeHPMR_e_HybSysSt_Value: accessed-variable=VeHPMR_e_HybSysSt.Value, variation-point={short-label=vpIN_VeHPMR_e_HybSysSt_Value, sw-syscond=1}
            IN_VeOBCR_e_ChargingLevel_Value: accessed-variable=VeOBCR_e_ChargingLevel.Value, variation-point={short-label=vpIN_VeOBCR_e_ChargingLevel_Value, sw-syscond=1}
            IN_VePDTR_e_EngOrBattPwrDschg_State_Value: accessed-variable=VePDTR_e_EngOrBattPwrDschg_State.Value, variation-point={short-label=vpIN_VePDTR_e_EngOrBattPwrDschg_State_Value, sw-syscond=1}
            IN_VePLTR_b_InFieldMode_Value: accessed-variable=VePLTR_b_InFieldMode.Value, variation-point={short-label=vpIN_VePLTR_b_InFieldMode_Value, sw-syscond=1}
            IN_VePMIR_b_LTActvPumpDryRun_FA_Value: accessed-variable=VePMIR_b_LTActvPumpDryRun_FA.Value, variation-point={short-label=vpIN_VePMIR_b_LTActvPumpDryRun_FA_Value, sw-syscond=1}
            IN_VePMIR_e_LTActvPumpDryRun_Value: accessed-variable=VePMIR_e_LTActvPumpDryRun.Value, variation-point={short-label=vpIN_VePMIR_e_LTActvPumpDryRun_Value, sw-syscond=1}
            IN_VePMTR_b_ThrmlSystRly_EnblCmnd_Value: accessed-variable=VePMTR_b_ThrmlSystRly_EnblCmnd.Value, variation-point={short-label=vpIN_VePMTR_b_ThrmlSystRly_EnblCmnd_Value, sw-syscond=1}
            IN_VePMTR_e_ThrmlDevEnbl_Value: accessed-variable=VePMTR_e_ThrmlDevEnbl.Value, variation-point={short-label=vpIN_VePMTR_e_ThrmlDevEnbl_Value, sw-syscond=1}
            IN_VePMTR_e_ThrmlEnblRsn_Value: accessed-variable=VePMTR_e_ThrmlEnblRsn.Value, variation-point={short-label=vpIN_VePMTR_e_ThrmlEnblRsn_Value, sw-syscond=1}
            IN_VeRCVR_b_AC_ShtdwnRqst_Value: accessed-variable=VeRCVR_b_AC_ShtdwnRqst.Value, variation-point={short-label=vpIN_VeRCVR_b_AC_ShtdwnRqst_Value, sw-syscond=1}
            IN_VeRCVR_b_Chlr_OpenCompTransition_Value: accessed-variable=VeRCVR_b_Chlr_OpenCompTransition.Value, variation-point={short-label=vpIN_VeRCVR_b_Chlr_OpenCompTransition_Value, sw-syscond=1}
            IN_VeRCVR_b_EXV_PresSensrRA_Value: accessed-variable=VeRCVR_b_EXV_PresSensrRA.Value, variation-point={short-label=vpIN_VeRCVR_b_EXV_PresSensrRA_Value, sw-syscond=1}
            IN_VeRCVR_b_FtRfgtShtoff_VlvCmd_Value: accessed-variable=VeRCVR_b_FtRfgtShtoff_VlvCmd.Value, variation-point={short-label=vpIN_VeRCVR_b_FtRfgtShtoff_VlvCmd_Value, sw-syscond=1}
            IN_VeRCVR_b_RSVCompTransition_Value: accessed-variable=VeRCVR_b_RSVCompTransition.Value, variation-point={short-label=vpIN_VeRCVR_b_RSVCompTransition_Value, sw-syscond=1}
            IN_VeRCVR_p_eACSuctionPressure_Value: accessed-variable=VeRCVR_p_eACSuctionPressure.Value, variation-point={short-label=vpIN_VeRCVR_p_eACSuctionPressure_Value, sw-syscond=1}
            IN_VeTAIR_P_AC_CompElecPwr_Value: accessed-variable=VeTAIR_P_AC_CompElecPwr.Value, variation-point={short-label=vpIN_VeTAIR_P_AC_CompElecPwr_Value, sw-syscond=1}
            IN_VeTAIR_Pct_FrtBlwrCmd_Value: accessed-variable=VeTAIR_Pct_FrtBlwrCmd.Value, variation-point={short-label=vpIN_VeTAIR_Pct_FrtBlwrCmd_Value, sw-syscond=1}
            IN_VeTAIR_T_CompBoardTemp_Value: accessed-variable=VeTAIR_T_CompBoardTemp.Value, variation-point={short-label=vpIN_VeTAIR_T_CompBoardTemp_Value, sw-syscond=1}
            IN_VeTAIR_T_CompIGBTTemp_Value: accessed-variable=VeTAIR_T_CompIGBTTemp.Value, variation-point={short-label=vpIN_VeTAIR_T_CompIGBTTemp_Value, sw-syscond=1}
            IN_VeTAIR_T_FtEvapTmp_Value: accessed-variable=VeTAIR_T_FtEvapTmp.Value, variation-point={short-label=vpIN_VeTAIR_T_FtEvapTmp_Value, sw-syscond=1}
            IN_VeTAIR_T_FtEvapTmp_Tgt_Value: accessed-variable=VeTAIR_T_FtEvapTmp_Tgt.Value, variation-point={short-label=vpIN_VeTAIR_T_FtEvapTmp_Tgt_Value, sw-syscond=1}
            IN_VeTAIR_b_ACCompReq_Value: accessed-variable=VeTAIR_b_ACCompReq.Value, variation-point={short-label=vpIN_VeTAIR_b_ACCompReq_Value, sw-syscond=1}
            IN_VeTAIR_b_AC_CompElecPwr_FA_Value: accessed-variable=VeTAIR_b_AC_CompElecPwr_FA.Value, variation-point={short-label=vpIN_VeTAIR_b_AC_CompElecPwr_FA_Value, sw-syscond=1}
            IN_VeTAIR_b_CompBoardTemp_FA_Value: accessed-variable=VeTAIR_b_CompBoardTemp_FA.Value, variation-point={short-label=vpIN_VeTAIR_b_CompBoardTemp_FA_Value, sw-syscond=1}
            IN_VeTAIR_b_CompIGBTTemp_FA_Value: accessed-variable=VeTAIR_b_CompIGBTTemp_FA.Value, variation-point={short-label=vpIN_VeTAIR_b_CompIGBTTemp_FA_Value, sw-syscond=1}
            IN_VeTAIR_b_CompSpdFdb_FA_Value: accessed-variable=VeTAIR_b_CompSpdFdb_FA.Value, variation-point={short-label=vpIN_VeTAIR_b_CompSpdFdb_FA_Value, sw-syscond=1}
            IN_VeTAIR_b_CompSpdIncrReq_Value: accessed-variable=VeTAIR_b_CompSpdIncrReq.Value, variation-point={short-label=vpIN_VeTAIR_b_CompSpdIncrReq_Value, sw-syscond=1}
            IN_VeTAIR_b_FrtBlwrCmd_FA_Value: accessed-variable=VeTAIR_b_FrtBlwrCmd_FA.Value, variation-point={short-label=vpIN_VeTAIR_b_FrtBlwrCmd_FA_Value, sw-syscond=1}
            IN_VeTAIR_b_FtEvapTmp_FA_Value: accessed-variable=VeTAIR_b_FtEvapTmp_FA.Value, variation-point={short-label=vpIN_VeTAIR_b_FtEvapTmp_FA_Value, sw-syscond=1}
            IN_VeTAIR_b_FtEvapTmp_TgtFA_Value: accessed-variable=VeTAIR_b_FtEvapTmp_TgtFA.Value, variation-point={short-label=vpIN_VeTAIR_b_FtEvapTmp_TgtFA_Value, sw-syscond=1}
            IN_VeTAIR_b_HVAC_ECVD_CurrentActFA_Value: accessed-variable=VeTAIR_b_HVAC_ECVD_CurrentActFA.Value, variation-point={short-label=vpIN_VeTAIR_b_HVAC_ECVD_CurrentActFA_Value, sw-syscond=1}
            IN_VeTAIR_e_CompSpdTgt_IO_CntrlSt_Value: accessed-variable=VeTAIR_e_CompSpdTgt_IO_CntrlSt.Value, variation-point={short-label=vpIN_VeTAIR_e_CompSpdTgt_IO_CntrlSt_Value, sw-syscond=1}
            IN_VeTAIR_e_CompStat_Value: accessed-variable=VeTAIR_e_CompStat.Value, variation-point={short-label=vpIN_VeTAIR_e_CompStat_Value, sw-syscond=1}
            IN_VeTAIR_n_CompSpdFdb_Value: accessed-variable=VeTAIR_n_CompSpdFdb.Value, variation-point={short-label=vpIN_VeTAIR_n_CompSpdFdb_Value, sw-syscond=1}
            IN_VeTAIR_n_DVC_CompSpdTgt_Value: accessed-variable=VeTAIR_n_DVC_CompSpdTgt.Value, variation-point={short-label=vpIN_VeTAIR_n_DVC_CompSpdTgt_Value, sw-syscond=1}
            IN_VeTAIR_p_HghRfrgtPres_Value: accessed-variable=VeTAIR_p_HghRfrgtPres.Value, variation-point={short-label=vpIN_VeTAIR_p_HghRfrgtPres_Value, sw-syscond=1}
            IN_VeTHMR_P_PwrBdgt_PwrLimitAvail_Value: accessed-variable=VeTHMR_P_PwrBdgt_PwrLimitAvail.Value, variation-point={short-label=vpIN_VeTHMR_P_PwrBdgt_PwrLimitAvail_Value, sw-syscond=1}
            IN_VeTHMR_P_Rat_EAC_PwrBdgt_Avail_Value: accessed-variable=VeTHMR_P_Rat_EAC_PwrBdgt_Avail.Value, variation-point={short-label=vpIN_VeTHMR_P_Rat_EAC_PwrBdgt_Avail_Value, sw-syscond=1}
            IN_VeTHMR_T_PPCTIS_Arb_Value: accessed-variable=VeTHMR_T_PPCTIS_Arb.Value, variation-point={short-label=vpIN_VeTHMR_T_PPCTIS_Arb_Value, sw-syscond=1}
            IN_VeTHMR_b_ActRemCompDecision_Value: accessed-variable=VeTHMR_b_ActRemCompDecision.Value, variation-point={short-label=vpIN_VeTHMR_b_ActRemCompDecision_Value, sw-syscond=1}
            IN_VeTHMR_b_BattAllowed_Value: accessed-variable=VeTHMR_b_BattAllowed.Value, variation-point={short-label=vpIN_VeTHMR_b_BattAllowed_Value, sw-syscond=1}
            IN_VeTHMR_b_CabAllowed_Value: accessed-variable=VeTHMR_b_CabAllowed.Value, variation-point={short-label=vpIN_VeTHMR_b_CabAllowed_Value, sw-syscond=1}
            IN_VeTHMR_b_CabReq_NotAllow_Value: accessed-variable=VeTHMR_b_CabReq_NotAllow.Value, variation-point={short-label=vpIN_VeTHMR_b_CabReq_NotAllow_Value, sw-syscond=1}
            IN_VeTHMR_b_DeiceActv_Value: accessed-variable=VeTHMR_b_DeiceActv.Value, variation-point={short-label=vpIN_VeTHMR_b_DeiceActv_Value, sw-syscond=1}
            IN_VeTHMR_b_HTCV_RAEnbl_BattTmpHi_Value: accessed-variable=VeTHMR_b_HTCV_RAEnbl_BattTmpHi.Value, variation-point={short-label=vpIN_VeTHMR_b_HTCV_RAEnbl_BattTmpHi_Value, sw-syscond=1}
            IN_VeTHMR_b_RS_N_Or_NrmlPerWp_Value: accessed-variable=VeTHMR_b_RS_N_Or_NrmlPerWp.Value, variation-point={short-label=vpIN_VeTHMR_b_RS_N_Or_NrmlPerWp_Value, sw-syscond=1}
            IN_VeTHMR_dT_CellOverTemp_Value: accessed-variable=VeTHMR_dT_CellOverTemp.Value, variation-point={short-label=vpIN_VeTHMR_dT_CellOverTemp_Value, sw-syscond=1}
            IN_VeTHMR_e_AC_CompState_Value: accessed-variable=VeTHMR_e_AC_CompState.Value, variation-point={short-label=vpIN_VeTHMR_e_AC_CompState_Value, sw-syscond=1}
            IN_VeTHMR_e_BatThrmlSt_Value: accessed-variable=VeTHMR_e_BatThrmlSt.Value, variation-point={short-label=vpIN_VeTHMR_e_BatThrmlSt_Value, sw-syscond=1}
            IN_VeTHMR_e_CabCoolThermalState_Value: accessed-variable=VeTHMR_e_CabCoolThermalState.Value, variation-point={short-label=vpIN_VeTHMR_e_CabCoolThermalState_Value, sw-syscond=1}
            IN_VeTHMR_e_CabHeatThermalMode_Value: accessed-variable=VeTHMR_e_CabHeatThermalMode.Value, variation-point={short-label=vpIN_VeTHMR_e_CabHeatThermalMode_Value, sw-syscond=1}
            IN_VeTPCR_dT_PerWpCond_BatTmpErr_Value: accessed-variable=VeTPCR_dT_PerWpCond_BatTmpErr.Value, variation-point={short-label=vpIN_VeTPCR_dT_PerWpCond_BatTmpErr_Value, sw-syscond=1}
            IN_VeTRIR_e_HVACECOModeSts_Value: accessed-variable=VeTRIR_e_HVACECOModeSts.Value, variation-point={short-label=vpIN_VeTRIR_e_HVACECOModeSts_Value, sw-syscond=1}
            IN_VeVLDR_b_EXV_PressElctrFlt_FltDtct_Value: accessed-variable=VeVLDR_b_EXV_PressElctrFlt_FltDtct.Value, variation-point={short-label=vpIN_VeVLDR_b_EXV_PressElctrFlt_FltDtct_Value, sw-syscond=1}
            IN_VeVLDR_b_EXV_PressSens_FltDtct_Value: accessed-variable=VeVLDR_b_EXV_PressSens_FltDtct.Value, variation-point={short-label=vpIN_VeVLDR_b_EXV_PressSens_FltDtct_Value, sw-syscond=1}
            IN_VeVLDR_b_EXV_TempElctrFlt_FltDtct_Value: accessed-variable=VeVLDR_b_EXV_TempElctrFlt_FltDtct.Value, variation-point={short-label=vpIN_VeVLDR_b_EXV_TempElctrFlt_FltDtct_Value, sw-syscond=1}
            IN_VeVLDR_b_EXV_TempSens_FltDtct_Value: accessed-variable=VeVLDR_b_EXV_TempSens_FltDtct.Value, variation-point={short-label=vpIN_VeVLDR_b_EXV_TempSens_FltDtct_Value, sw-syscond=1}
        data-send-points:
          11 x access:
            OUT_VeACCR_n_CompSpdTgt_Value: accessed-variable=VeACCR_n_CompSpdTgt.Value, variation-point={short-label=vpOUT_VeACCR_n_CompSpdTgt_Value, sw-syscond=1}
            OUT_VeACCR_b_OilMigOpnVlv_Value: accessed-variable=VeACCR_b_OilMigOpnVlv.Value, variation-point={short-label=vpOUT_VeACCR_b_OilMigOpnVlv_Value, sw-syscond=1}
            OUT_VeACCR_b_eAC4CabInhibtd_Value: accessed-variable=VeACCR_b_eAC4CabInhibtd.Value, variation-point={short-label=vpOUT_VeACCR_b_eAC4CabInhibtd_Value, sw-syscond=1}
            OUT_VeACCR_b_OverTempImminent_Value: accessed-variable=VeACCR_b_OverTempImminent.Value, variation-point={short-label=vpOUT_VeACCR_b_OverTempImminent_Value, sw-syscond=1}
            OUT_VeACCR_n_FtERV_ShutMaxRPM_Value: accessed-variable=VeACCR_n_FtERV_ShutMaxRPM.Value, variation-point={short-label=vpOUT_VeACCR_n_FtERV_ShutMaxRPM_Value, sw-syscond=1}
            OUT_VeACCR_P_HVAC_CompPwrUsage_Value: accessed-variable=VeACCR_P_HVAC_CompPwrUsage.Value, variation-point={short-label=vpOUT_VeACCR_P_HVAC_CompPwrUsage_Value, sw-syscond=1}
            OUT_VeACCR_e_AC_CompEnb_Value: accessed-variable=VeACCR_e_AC_CompEnb.Value, variation-point={short-label=vpOUT_VeACCR_e_AC_CompEnb_Value, sw-syscond=1}
            OUT_VeACCR_b_AC_ClutchReq_Value: accessed-variable=VeACCR_b_AC_ClutchReq.Value, variation-point={short-label=vpOUT_VeACCR_b_AC_ClutchReq_Value, sw-syscond=1}
            OUT_VeACCR_I_ECVD_CurrentTgt_Value: accessed-variable=VeACCR_I_ECVD_CurrentTgt.Value, variation-point={short-label=vpOUT_VeACCR_I_ECVD_CurrentTgt_Value, sw-syscond=1}
            OUT_VeACCR_I_FtERVShtMaxCrrnt_Value: accessed-variable=VeACCR_I_FtERVShtMaxCrrnt.Value, variation-point={short-label=vpOUT_VeACCR_I_FtERVShtMaxCrrnt_Value, sw-syscond=1}
            OUT_VeACCR_n_ChillerV_OpenMaxRPM_Value: accessed-variable=VeACCR_n_ChillerV_OpenMaxRPM.Value, variation-point={short-label=vpOUT_VeACCR_n_ChillerV_OpenMaxRPM_Value, sw-syscond=1}
        read-local-variables:
          access RV_OilMigOpnVlv_write_IRV: accessed-variable=OilMigOpnVlv_write_IRV, variation-point={short-label=vpRV_OilMigOpnVlv_write_IRV, sw-syscond=1}
          access RV_OverTempImminent_write_IRV: accessed-variable=OverTempImminent_write_IRV, variation-point={short-label=vpRV_OverTempImminent_write_IRV, sw-syscond=1}
        written-local-variables:
          access WV_OilMigOpnVlv_write_IRV: accessed-variable=OilMigOpnVlv_write_IRV, variation-point={short-label=vpWV_OilMigOpnVlv_write_IRV, sw-syscond=1}
          access WV_OverTempImminent_write_IRV: accessed-variable=OverTempImminent_write_IRV, variation-point={short-label=vpWV_OverTempImminent_write_IRV, sw-syscond=1}
      variation point proxy Variant_ACCR_FUNC_1: category=CONDITION, condition-access=0
      variation point proxy Variant_ACCR_FUNC_2: category=CONDITION, condition-access=1
      variation point proxy Variant_ACCR_FUNC_3: category=CONDITION, condition-access=0
